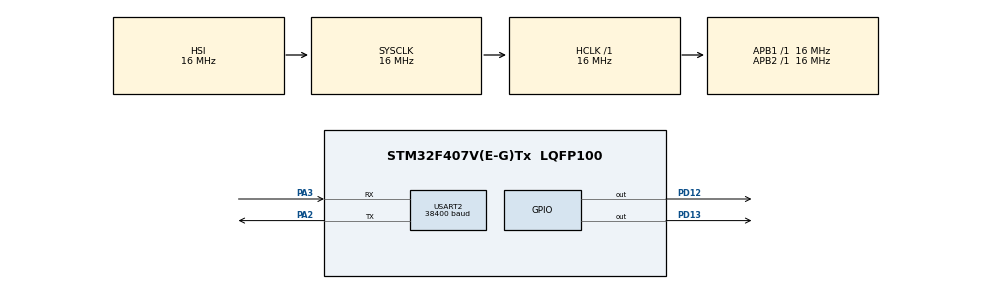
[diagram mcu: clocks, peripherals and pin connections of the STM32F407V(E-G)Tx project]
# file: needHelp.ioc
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Mcu.Family=STM32F4
Mcu.Name=STM32F407V(E-G)Tx
Mcu.Package=LQFP100
NVIC.PriorityGroup=NVIC_PRIORITYGROUP_4
NVIC.USART2_IRQn=true\:0\:0\:false\:false\:true\:true\:true
PA2.Mode=Asynchronous
PA2.Signal=USART2_TX
PA3.Mode=Asynchronous
PA3.Signal=USART2_RX
PD12.Signal=GPIO_Output
PD13.Signal=GPIO_Output
ProjectManager.HeapSize=0x200
ProjectManager.StackSize=0x400
ProjectManager.TargetToolchain=MDK-ARM V5.27
RCC.AHBFreq_Value=16000000
RCC.APB1Freq_Value=16000000
RCC.APB2Freq_Value=16000000
RCC.CortexFreq_Value=16000000
RCC.HSE_VALUE=25000000
RCC.HSI_VALUE=16000000
RCC.LSE_VALUE=32768
RCC.SYSCLKFreq_VALUE=16000000
RCC.VCOOutputFreq_Value=192000000
USART2.BaudRate=38400
USART2.VirtualMode=VM_ASYNC
board=custom

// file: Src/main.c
/* USER CODE BEGIN Header */
/**
  ******************************************************************************
  * @file           : main.c
  * @brief          : Main program body
  ******************************************************************************
  * @attention
  *
  * <h2><center>&copy; Copyright (c) 2019 STMicroelectronics.
  * All rights reserved.</center></h2>
  *
  * This software component is licensed by ST under BSD 3-Clause license,
  * the "License"; You may not use this file except in compliance with the
  * License. You may obtain a copy of the License at:
  *                        opensource.org/licenses/BSD-3-Clause
  *
  ******************************************************************************
  */
/* USER CODE END Header */

#include "main.h"
#include "string.h"

UART_HandleTypeDef huart2;
uint8_t rxData[30];

void SystemClock_Config(void);
static void MX_GPIO_Init(void);
static void MX_USART2_UART_Init(void);

int main(void)
{

  /* MCU Configuration--------------------------------------------------------*/

  /* Reset of all peripherals, Initializes the Flash interface and the Systick. */
  HAL_Init();

  /* Configure the system clock */
  SystemClock_Config();

  /* Initialize all configured peripherals */
  MX_GPIO_Init();
  MX_USART2_UART_Init();
  /* USER CODE BEGIN 2 */
	char txData[30] = "Hello World\r\n";
	/*
	strcpy(txData, "AT\r\n");
	HAL_UART_Transmit(&huart2, (uint8_t*)txData,strlen(txData),10);
	HAL_Delay(500);
	strcpy(txData,"AT+Name=STM32\r\n");
	HAL_UART_Transmit(&huart2, (uint8_t*)txData,strlen(txData),10);
	HAL_Delay(500);
	strcpy(txData,"AT+PSWD=490\r\n");
	HAL_UART_Transmit(&huart2, (uint8_t*)txData,strlen(txData),10);
	HAL_Delay(500);
	strcpy(txData,"AT+ROLE=1\r\n"); //  mode 1 for master
	HAL_UART_Transmit(&huart2, (uint8_t*)txData,strlen(txData),10);
	HAL_Delay(500);
	//strcpy(txData,"AT+CMODE=0\r\n"); //  mode 1 for master
	//HAL_UART_Transmit(&huart2, (uint8_t*)txData,strlen(txData),10);
	HAL_Delay(500);

	//strcpy(txData,"AT+BIND=98d3,32,7111b3\r\n"); //  mode 1 for master
	//HAL_UART_Transmit(&huart2, (uint8_t*)txData,strlen(txData),10);
	HAL_Delay(500);
	strcpy(txData,"AT+UART=38400,1,0\r\n"); // stop bit 1, parity 0
	HAL_UART_Transmit(&huart2, (uint8_t*)txData,strlen(txData),10);
	HAL_Delay(500);

	strcpy(txData,"AT+RESET\r\n");
	HAL_UART_Transmit(&huart2, (uint8_t*)txData,strlen(txData),10);
	HAL_Delay(500);
	HAL_GPIO_WritePin(GPIOD,GPIO_PIN_13,GPIO_PIN_SET);
	*/
  /* USER CODE END 2 */

  /* Infinite loop */
  while (1)
  {
		HAL_UART_Receive(&huart2,rxData,sizeof(rxData)/sizeof(uint8_t),100);
		if(rxData[0] == 'O' && rxData[1] == 'K'){
			HAL_GPIO_TogglePin(GPIOD,GPIO_PIN_13);
		}
  }
}

void SystemClock_Config(void)
{
  RCC_OscInitTypeDef RCC_OscInitStruct = {0};
  RCC_ClkInitTypeDef RCC_ClkInitStruct = {0};

  /** Configure the main internal regulator output voltage
  */
  __HAL_RCC_PWR_CLK_ENABLE();
  __HAL_PWR_VOLTAGESCALING_CONFIG(PWR_REGULATOR_VOLTAGE_SCALE1);
  /** Initializes the CPU, AHB and APB busses clocks
  */
  RCC_OscInitStruct.OscillatorType = RCC_OSCILLATORTYPE_HSI;
  RCC_OscInitStruct.HSIState = RCC_HSI_ON;
  RCC_OscInitStruct.HSICalibrationValue = RCC_HSICALIBRATION_DEFAULT;
  RCC_OscInitStruct.PLL.PLLState = RCC_PLL_NONE;
  if (HAL_RCC_OscConfig(&RCC_OscInitStruct) != HAL_OK)
  {
    Error_Handler();
  }
  /** Initializes the CPU, AHB and APB busses clocks
  */
  RCC_ClkInitStruct.ClockType = RCC_CLOCKTYPE_HCLK|RCC_CLOCKTYPE_SYSCLK
                              |RCC_CLOCKTYPE_PCLK1|RCC_CLOCKTYPE_PCLK2;
  RCC_ClkInitStruct.SYSCLKSource = RCC_SYSCLKSOURCE_HSI;
  RCC_ClkInitStruct.AHBCLKDivider = RCC_SYSCLK_DIV1;
  RCC_ClkInitStruct.APB1CLKDivider = RCC_HCLK_DIV1;
  RCC_ClkInitStruct.APB2CLKDivider = RCC_HCLK_DIV1;

  if (HAL_RCC_ClockConfig(&RCC_ClkInitStruct, FLASH_LATENCY_0) != HAL_OK)
  {
    Error_Handler();
  }
}

static void MX_USART2_UART_Init(void)
{

  huart2.Instance = USART2;
  huart2.Init.BaudRate = 38400;
  huart2.Init.WordLength = UART_WORDLENGTH_8B;
  huart2.Init.StopBits = UART_STOPBITS_1;
  huart2.Init.Parity = UART_PARITY_NONE;
  huart2.Init.Mode = UART_MODE_TX_RX;
  huart2.Init.HwFlowCtl = UART_HWCONTROL_NONE;
  huart2.Init.OverSampling = UART_OVERSAMPLING_16;
  if (HAL_UART_Init(&huart2) != HAL_OK)
  {
    Error_Handler();
  }

}

static void MX_GPIO_Init(void)
{
  GPIO_InitTypeDef GPIO_InitStruct = {0};

  /* GPIO Ports Clock Enable */
  __HAL_RCC_GPIOA_CLK_ENABLE();
  __HAL_RCC_GPIOD_CLK_ENABLE();

  /*Configure GPIO pin Output Level */
  HAL_GPIO_WritePin(GPIOD, GPIO_PIN_12|GPIO_PIN_13, GPIO_PIN_RESET);

  /*Configure GPIO pins : PD12 PD13 */
  GPIO_InitStruct.Pin = GPIO_PIN_12|GPIO_PIN_13;
  GPIO_InitStruct.Mode = GPIO_MODE_OUTPUT_PP;
  GPIO_InitStruct.Pull = GPIO_NOPULL;
  GPIO_InitStruct.Speed = GPIO_SPEED_FREQ_LOW;
  HAL_GPIO_Init(GPIOD, &GPIO_InitStruct);

}

void Error_Handler(void)
{
}

/************************ (C) COPYRIGHT STMicroelectronics *****END OF FILE****/
